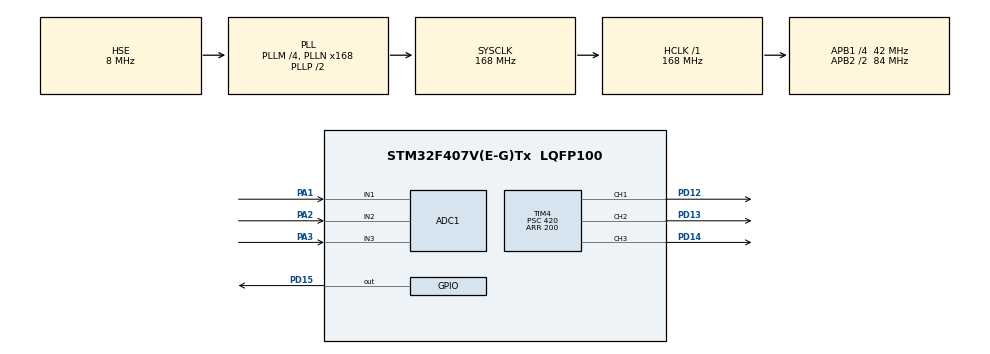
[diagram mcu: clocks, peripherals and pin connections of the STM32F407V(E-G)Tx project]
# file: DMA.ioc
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ADC1.Channel-0\#ChannelRegularConversion=ADC_CHANNEL_1
ADC1.Channel-1\#ChannelRegularConversion=ADC_CHANNEL_2
ADC1.Channel-2\#ChannelRegularConversion=ADC_CHANNEL_3
ADC1.DMAContinuousRequests=ENABLE
ADC1.EOCSelection=ADC_EOC_SEQ_CONV
ADC1.ExternalTrigConv=ADC_EXTERNALTRIGCONV_T2_TRGO
ADC1.NbrOfConversion=3
ADC1.NbrOfConversionFlag=1
ADC1.Rank-0\#ChannelRegularConversion=1
ADC1.Rank-1\#ChannelRegularConversion=2
ADC1.Rank-2\#ChannelRegularConversion=3
ADC1.SamplingTime-0\#ChannelRegularConversion=ADC_SAMPLETIME_84CYCLES
ADC1.SamplingTime-1\#ChannelRegularConversion=ADC_SAMPLETIME_84CYCLES
ADC1.SamplingTime-2\#ChannelRegularConversion=ADC_SAMPLETIME_84CYCLES
ADC1.ScanConvMode=ENABLE
ADC1.master=1
Dma.ADC1.0.Direction=DMA_PERIPH_TO_MEMORY
Dma.ADC1.0.FIFOMode=DMA_FIFOMODE_DISABLE
Dma.ADC1.0.Instance=DMA2_Stream0
Dma.ADC1.0.MemDataAlignment=DMA_MDATAALIGN_HALFWORD
Dma.ADC1.0.MemInc=DMA_MINC_ENABLE
Dma.ADC1.0.Mode=DMA_CIRCULAR
Dma.ADC1.0.PeriphDataAlignment=DMA_PDATAALIGN_HALFWORD
Dma.ADC1.0.PeriphInc=DMA_PINC_DISABLE
Dma.ADC1.0.Priority=DMA_PRIORITY_LOW
Dma.Request0=ADC1
Mcu.Family=STM32F4
Mcu.Name=STM32F407V(E-G)Tx
Mcu.Package=LQFP100
NVIC.ADC_IRQn=true\:2\:0\:true\:false\:true\:true
NVIC.DMA2_Stream0_IRQn=true\:0\:0\:false\:false\:true\:false
NVIC.PriorityGroup=NVIC_PRIORITYGROUP_4
PA1.Signal=ADCx_IN1
PA13.Mode=Serial_Wire
PA13.Signal=SYS_JTMS-SWDIO
PA14.Mode=Serial_Wire
PA14.Signal=SYS_JTCK-SWCLK
PA2.Signal=ADCx_IN2
PA3.Signal=ADCx_IN3
PD12.Signal=S_TIM4_CH1
PD13.Signal=S_TIM4_CH2
PD14.Signal=S_TIM4_CH3
PD15.Signal=GPIO_Output
PH0-OSC_IN.Mode=HSE-External-Oscillator
PH0-OSC_IN.Signal=RCC_OSC_IN
PH1-OSC_OUT.Mode=HSE-External-Oscillator
PH1-OSC_OUT.Signal=RCC_OSC_OUT
ProjectManager.HeapSize=0x200
ProjectManager.StackSize=0x400
ProjectManager.TargetToolchain=TrueSTUDIO
RCC.48MHZClocksFreq_Value=84000000
RCC.AHBFreq_Value=168000000
RCC.APB1CLKDivider=RCC_HCLK_DIV4
RCC.APB1Freq_Value=42000000
RCC.APB1TimFreq_Value=84000000
RCC.APB2CLKDivider=RCC_HCLK_DIV2
RCC.APB2Freq_Value=84000000
RCC.APB2TimFreq_Value=168000000
RCC.CortexFreq_Value=168000000
RCC.HCLKFreq_Value=168000000
RCC.HSE_VALUE=8000000
RCC.HSI_VALUE=16000000
RCC.LSE_VALUE=32768
RCC.PLLM=4
RCC.PLLN=168
RCC.PLLSourceVirtual=RCC_PLLSOURCE_HSE
RCC.SYSCLKFreq_VALUE=168000000
RCC.SYSCLKSource=RCC_SYSCLKSOURCE_PLLCLK
RCC.VCOOutputFreq_Value=336000000
SH.ADCx_IN1.0=ADC1_IN1,IN1
SH.ADCx_IN2.0=ADC1_IN2,IN2
SH.ADCx_IN3.0=ADC1_IN3,IN3
SH.S_TIM4_CH1.0=TIM4_CH1,PWM Generation1 CH1
SH.S_TIM4_CH2.0=TIM4_CH2,PWM Generation2 CH2
SH.S_TIM4_CH3.0=TIM4_CH3,PWM Generation3 CH3
TIM2.Period=9999
TIM2.Prescaler=839
TIM2.TIM_MasterOutputTrigger=TIM_TRGO_UPDATE
TIM4.Channel-PWM\ Generation1\ CH1=TIM_CHANNEL_1
TIM4.Channel-PWM\ Generation2\ CH2=TIM_CHANNEL_2
TIM4.Channel-PWM\ Generation3\ CH3=TIM_CHANNEL_3
TIM4.Period=200
TIM4.Prescaler=420
VP_TIM2_VS_ClockSourceINT.Mode=Internal
VP_TIM4_VS_ClockSourceINT.Mode=Internal
board=custom

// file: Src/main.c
/**
  ******************************************************************************
  * @file           : main.c
  * @brief          : Main program body
  ******************************************************************************
  ** This notice applies to any and all portions of this file
  * that are not between comment pairs USER CODE BEGIN and
  * USER CODE END. Other portions of this file, whether
  * inserted by the user or by software development tools
  * are owned by their respective copyright owners.
  *
  * COPYRIGHT(c) 2018 STMicroelectronics
  *
  * Redistribution and use in source and binary forms, with or without modification,
  * are permitted provided that the following conditions are met:
  *   1. Redistributions of source code must retain the above copyright notice,
  *      this list of conditions and the following disclaimer.
  *   2. Redistributions in binary form must reproduce the above copyright notice,
  *      this list of conditions and the following disclaimer in the documentation
  *      and/or other materials provided with the distribution.
  *   3. Neither the name of STMicroelectronics nor the names of its contributors
  *      may be used to endorse or promote products derived from this software
  *      without specific prior written permission.
  *
  * THIS SOFTWARE IS PROVIDED BY THE COPYRIGHT HOLDERS AND CONTRIBUTORS "AS IS"
  * AND ANY EXPRESS OR IMPLIED WARRANTIES, INCLUDING, BUT NOT LIMITED TO, THE
  * IMPLIED WARRANTIES OF MERCHANTABILITY AND FITNESS FOR A PARTICULAR PURPOSE ARE
  * DISCLAIMED. IN NO EVENT SHALL THE COPYRIGHT HOLDER OR CONTRIBUTORS BE LIABLE
  * FOR ANY DIRECT, INDIRECT, INCIDENTAL, SPECIAL, EXEMPLARY, OR CONSEQUENTIAL
  * DAMAGES (INCLUDING, BUT NOT LIMITED TO, PROCUREMENT OF SUBSTITUTE GOODS OR
  * SERVICES; LOSS OF USE, DATA, OR PROFITS; OR BUSINESS INTERRUPTION) HOWEVER
  * CAUSED AND ON ANY THEORY OF LIABILITY, WHETHER IN CONTRACT, STRICT LIABILITY,
  * OR TORT (INCLUDING NEGLIGENCE OR OTHERWISE) ARISING IN ANY WAY OUT OF THE USE
  * OF THIS SOFTWARE, EVEN IF ADVISED OF THE POSSIBILITY OF SUCH DAMAGE.
  *
  ******************************************************************************
  */
#include "main.h"
#include "stm32f4xx_hal.h"

/* USER CODE BEGIN Includes */
#include "app.h"
/* USER CODE END Includes */

ADC_HandleTypeDef hadc1;
DMA_HandleTypeDef hdma_adc1;

TIM_HandleTypeDef htim2;
TIM_HandleTypeDef htim4;

/* USER CODE BEGIN PV */
/* Private variables ---------------------------------------------------------*/

/* USER CODE END PV */

void SystemClock_Config(void);
static void MX_GPIO_Init(void);
static void MX_DMA_Init(void);
static void MX_TIM4_Init(void);
static void MX_TIM2_Init(void);
static void MX_ADC1_Init(void);

void HAL_TIM_MspPostInit(TIM_HandleTypeDef *htim);

/* USER CODE BEGIN PFP */
/* Private function prototypes -----------------------------------------------*/

/* USER CODE END PFP */

int main(void)
{

  /* MCU Configuration----------------------------------------------------------*/

  /* Reset of all peripherals, Initializes the Flash interface and the Systick. */
  HAL_Init();

  /* Configure the system clock */
  SystemClock_Config();

  /* Initialize all configured peripherals */
  MX_GPIO_Init();
  MX_DMA_Init();
  MX_TIM4_Init();
  MX_TIM2_Init();
  MX_ADC1_Init();

  /* USER CODE BEGIN 2 */
  app_init();

  /* USER CODE END 2 */

  /* Infinite loop */
  while (1)
  {

  /* USER CODE BEGIN 3 */

	  __WFI();
  }
  /* USER CODE END 3 */

}

void SystemClock_Config(void)
{

  RCC_OscInitTypeDef RCC_OscInitStruct;
  RCC_ClkInitTypeDef RCC_ClkInitStruct;

    /**Configure the main internal regulator output voltage
    */
  __HAL_RCC_PWR_CLK_ENABLE();

  __HAL_PWR_VOLTAGESCALING_CONFIG(PWR_REGULATOR_VOLTAGE_SCALE1);

    /**Initializes the CPU, AHB and APB busses clocks
    */
  RCC_OscInitStruct.OscillatorType = RCC_OSCILLATORTYPE_HSE;
  RCC_OscInitStruct.HSEState = RCC_HSE_ON;
  RCC_OscInitStruct.PLL.PLLState = RCC_PLL_ON;
  RCC_OscInitStruct.PLL.PLLSource = RCC_PLLSOURCE_HSE;
  RCC_OscInitStruct.PLL.PLLM = 4;
  RCC_OscInitStruct.PLL.PLLN = 168;
  RCC_OscInitStruct.PLL.PLLP = RCC_PLLP_DIV2;
  RCC_OscInitStruct.PLL.PLLQ = 4;
  if (HAL_RCC_OscConfig(&RCC_OscInitStruct) != HAL_OK)
  {
    _Error_Handler(__FILE__, __LINE__);
  }

    /**Initializes the CPU, AHB and APB busses clocks
    */
  RCC_ClkInitStruct.ClockType = RCC_CLOCKTYPE_HCLK|RCC_CLOCKTYPE_SYSCLK
                              |RCC_CLOCKTYPE_PCLK1|RCC_CLOCKTYPE_PCLK2;
  RCC_ClkInitStruct.SYSCLKSource = RCC_SYSCLKSOURCE_PLLCLK;
  RCC_ClkInitStruct.AHBCLKDivider = RCC_SYSCLK_DIV1;
  RCC_ClkInitStruct.APB1CLKDivider = RCC_HCLK_DIV4;
  RCC_ClkInitStruct.APB2CLKDivider = RCC_HCLK_DIV2;

  if (HAL_RCC_ClockConfig(&RCC_ClkInitStruct, FLASH_LATENCY_5) != HAL_OK)
  {
    _Error_Handler(__FILE__, __LINE__);
  }

    /**Configure the Systick interrupt time
    */
  HAL_SYSTICK_Config(HAL_RCC_GetHCLKFreq()/1000);

    /**Configure the Systick
    */
  HAL_SYSTICK_CLKSourceConfig(SYSTICK_CLKSOURCE_HCLK);

  /* SysTick_IRQn interrupt configuration */
  HAL_NVIC_SetPriority(SysTick_IRQn, 0, 0);
}

/* ADC1 init function */
static void MX_ADC1_Init(void)
{

  ADC_ChannelConfTypeDef sConfig;

    /**Configure the global features of the ADC (Clock, Resolution, Data Alignment and number of conversion)
    */
  hadc1.Instance = ADC1;
  hadc1.Init.ClockPrescaler = ADC_CLOCK_SYNC_PCLK_DIV4;
  hadc1.Init.Resolution = ADC_RESOLUTION_12B;
  hadc1.Init.ScanConvMode = ENABLE;
  hadc1.Init.ContinuousConvMode = DISABLE;
  hadc1.Init.DiscontinuousConvMode = DISABLE;
  hadc1.Init.ExternalTrigConvEdge = ADC_EXTERNALTRIGCONVEDGE_RISING;
  hadc1.Init.ExternalTrigConv = ADC_EXTERNALTRIGCONV_T2_TRGO;
  hadc1.Init.DataAlign = ADC_DATAALIGN_RIGHT;
  hadc1.Init.NbrOfConversion = 3;
  hadc1.Init.DMAContinuousRequests = ENABLE;
  hadc1.Init.EOCSelection = ADC_EOC_SEQ_CONV;
  if (HAL_ADC_Init(&hadc1) != HAL_OK)
  {
    _Error_Handler(__FILE__, __LINE__);
  }

    /**Configure for the selected ADC regular channel its corresponding rank in the sequencer and its sample time.
    */
  sConfig.Channel = ADC_CHANNEL_1;
  sConfig.Rank = 1;
  sConfig.SamplingTime = ADC_SAMPLETIME_84CYCLES;
  if (HAL_ADC_ConfigChannel(&hadc1, &sConfig) != HAL_OK)
  {
    _Error_Handler(__FILE__, __LINE__);
  }

    /**Configure for the selected ADC regular channel its corresponding rank in the sequencer and its sample time.
    */
  sConfig.Channel = ADC_CHANNEL_2;
  sConfig.Rank = 2;
  if (HAL_ADC_ConfigChannel(&hadc1, &sConfig) != HAL_OK)
  {
    _Error_Handler(__FILE__, __LINE__);
  }

    /**Configure for the selected ADC regular channel its corresponding rank in the sequencer and its sample time.
    */
  sConfig.Channel = ADC_CHANNEL_3;
  sConfig.Rank = 3;
  if (HAL_ADC_ConfigChannel(&hadc1, &sConfig) != HAL_OK)
  {
    _Error_Handler(__FILE__, __LINE__);
  }

}

/* TIM2 init function */
static void MX_TIM2_Init(void)
{

  TIM_ClockConfigTypeDef sClockSourceConfig;
  TIM_MasterConfigTypeDef sMasterConfig;

  htim2.Instance = TIM2;
  htim2.Init.Prescaler = 839;
  htim2.Init.CounterMode = TIM_COUNTERMODE_UP;
  htim2.Init.Period = 9999;
  htim2.Init.ClockDivision = TIM_CLOCKDIVISION_DIV1;
  if (HAL_TIM_Base_Init(&htim2) != HAL_OK)
  {
    _Error_Handler(__FILE__, __LINE__);
  }

  sClockSourceConfig.ClockSource = TIM_CLOCKSOURCE_INTERNAL;
  if (HAL_TIM_ConfigClockSource(&htim2, &sClockSourceConfig) != HAL_OK)
  {
    _Error_Handler(__FILE__, __LINE__);
  }

  sMasterConfig.MasterOutputTrigger = TIM_TRGO_UPDATE;
  sMasterConfig.MasterSlaveMode = TIM_MASTERSLAVEMODE_DISABLE;
  if (HAL_TIMEx_MasterConfigSynchronization(&htim2, &sMasterConfig) != HAL_OK)
  {
    _Error_Handler(__FILE__, __LINE__);
  }

}

/* TIM4 init function */
static void MX_TIM4_Init(void)
{

  TIM_ClockConfigTypeDef sClockSourceConfig;
  TIM_MasterConfigTypeDef sMasterConfig;
  TIM_OC_InitTypeDef sConfigOC;

  htim4.Instance = TIM4;
  htim4.Init.Prescaler = 420;
  htim4.Init.CounterMode = TIM_COUNTERMODE_UP;
  htim4.Init.Period = 200;
  htim4.Init.ClockDivision = TIM_CLOCKDIVISION_DIV1;
  if (HAL_TIM_Base_Init(&htim4) != HAL_OK)
  {
    _Error_Handler(__FILE__, __LINE__);
  }

  sClockSourceConfig.ClockSource = TIM_CLOCKSOURCE_INTERNAL;
  if (HAL_TIM_ConfigClockSource(&htim4, &sClockSourceConfig) != HAL_OK)
  {
    _Error_Handler(__FILE__, __LINE__);
  }

  if (HAL_TIM_PWM_Init(&htim4) != HAL_OK)
  {
    _Error_Handler(__FILE__, __LINE__);
  }

  sMasterConfig.MasterOutputTrigger = TIM_TRGO_RESET;
  sMasterConfig.MasterSlaveMode = TIM_MASTERSLAVEMODE_DISABLE;
  if (HAL_TIMEx_MasterConfigSynchronization(&htim4, &sMasterConfig) != HAL_OK)
  {
    _Error_Handler(__FILE__, __LINE__);
  }

  sConfigOC.OCMode = TIM_OCMODE_PWM1;
  sConfigOC.Pulse = 0;
  sConfigOC.OCPolarity = TIM_OCPOLARITY_HIGH;
  sConfigOC.OCFastMode = TIM_OCFAST_DISABLE;
  if (HAL_TIM_PWM_ConfigChannel(&htim4, &sConfigOC, TIM_CHANNEL_1) != HAL_OK)
  {
    _Error_Handler(__FILE__, __LINE__);
  }

  if (HAL_TIM_PWM_ConfigChannel(&htim4, &sConfigOC, TIM_CHANNEL_2) != HAL_OK)
  {
    _Error_Handler(__FILE__, __LINE__);
  }

  if (HAL_TIM_PWM_ConfigChannel(&htim4, &sConfigOC, TIM_CHANNEL_3) != HAL_OK)
  {
    _Error_Handler(__FILE__, __LINE__);
  }

  HAL_TIM_MspPostInit(&htim4);

}

static void MX_DMA_Init(void)
{
  /* DMA controller clock enable */
  __HAL_RCC_DMA2_CLK_ENABLE();

  /* DMA interrupt init */
  /* DMA2_Stream0_IRQn interrupt configuration */
  HAL_NVIC_SetPriority(DMA2_Stream0_IRQn, 0, 0);
  HAL_NVIC_EnableIRQ(DMA2_Stream0_IRQn);

}

/** Configure pins as
        * Analog
        * Input
        * Output
        * EVENT_OUT
        * EXTI
*/
static void MX_GPIO_Init(void)
{

  GPIO_InitTypeDef GPIO_InitStruct;

  /* GPIO Ports Clock Enable */
  __HAL_RCC_GPIOH_CLK_ENABLE();
  __HAL_RCC_GPIOA_CLK_ENABLE();
  __HAL_RCC_GPIOD_CLK_ENABLE();

  /*Configure GPIO pin Output Level */
  HAL_GPIO_WritePin(GPIOD, GPIO_PIN_15, GPIO_PIN_RESET);

  /*Configure GPIO pin : PD15 */
  GPIO_InitStruct.Pin = GPIO_PIN_15;
  GPIO_InitStruct.Mode = GPIO_MODE_OUTPUT_PP;
  GPIO_InitStruct.Pull = GPIO_NOPULL;
  GPIO_InitStruct.Speed = GPIO_SPEED_FREQ_LOW;
  HAL_GPIO_Init(GPIOD, &GPIO_InitStruct);

}

void _Error_Handler(char *file, int line)
{
  while(1)
  {
  }
}

/************************ (C) COPYRIGHT STMicroelectronics *****END OF FILE****/
